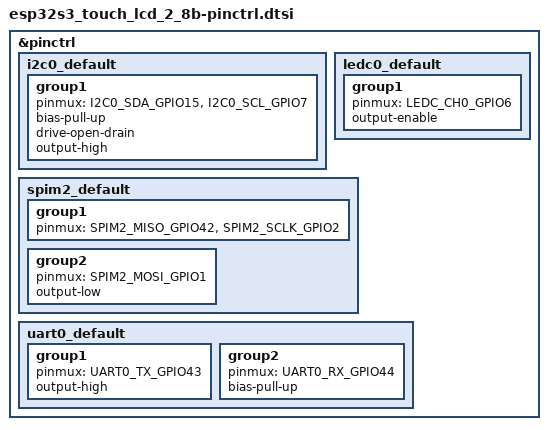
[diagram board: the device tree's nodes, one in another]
/*
 * SPDX-FileCopyrightText: Copyright The Zephyr Project Contributors
 * SPDX-License-Identifier: Apache-2.0
 */

#include <zephyr/dt-bindings/pinctrl/esp32s3-pinctrl.h>

&pinctrl {
	i2c0_default: i2c0_default {
		group1 {
			pinmux = <I2C0_SDA_GPIO15>, <I2C0_SCL_GPIO7>;
			bias-pull-up;
			drive-open-drain;
			output-high;
		};
	};

	ledc0_default: ledc0_default {
		group1 {
			pinmux = <LEDC_CH0_GPIO6>;
			output-enable;
		};
	};

	spim2_default: spim2_default {
		group1 {
			pinmux = <SPIM2_MISO_GPIO42>, <SPIM2_SCLK_GPIO2>;
		};

		group2 {
			pinmux = <SPIM2_MOSI_GPIO1>;
			output-low;
		};
	};

	uart0_default: uart0_default {
		group1 {
			pinmux = <UART0_TX_GPIO43>;
			output-high;
		};

		group2 {
			pinmux = <UART0_RX_GPIO44>;
			bias-pull-up;
		};
	};
};
